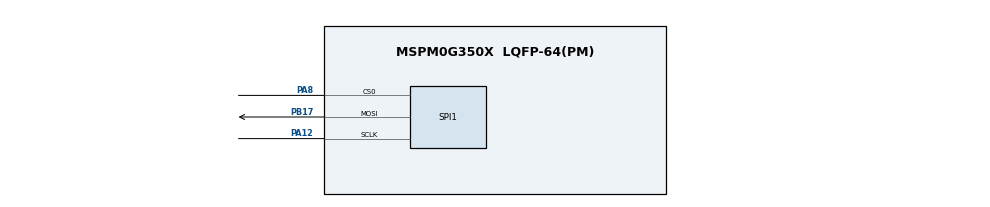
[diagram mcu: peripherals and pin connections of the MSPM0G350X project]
/**
 * @cliArgs --device "MSPM0G350X" --part "Default" --package "LQFP-64(PM)" --product "mspm0_sdk@2.05.01.01"
 * @versions {"tool":"1.24.0+4110"}
 */

/**
 * Import the modules used in this configuration.
 */
const SPI    = scripting.addModule("/ti/driverlib/SPI", {}, false);
const SPI1   = SPI.addInstance();
const SYSCTL = scripting.addModule("/ti/driverlib/SYSCTL");
const TIMER  = scripting.addModule("/ti/driverlib/TIMER", {}, false);
const TIMER1 = TIMER.addInstance();

/**
 * Write custom configuration values to the imported modules.
 */
const divider9       = system.clockTree["UDIV"];
divider9.divideValue = 2;

const multiplier2         = system.clockTree["PLL_QDIV"];
multiplier2.multiplyValue = 4;

const mux4       = system.clockTree["EXHFMUX"];
mux4.inputSelect = "EXHFMUX_XTAL";

const mux8       = system.clockTree["HSCLKMUX"];
mux8.inputSelect = "HSCLKMUX_SYSPLL0";

const mux12       = system.clockTree["SYSPLLMUX"];
mux12.inputSelect = "zSYSPLLMUX_HFCLK";

const pinFunction4       = system.clockTree["HFXT"];
pinFunction4.inputFreq   = 40;
pinFunction4.enable      = true;
pinFunction4.HFXTStartup = 16;

SPI1.$name                      = "SPI_0";
SPI1.polarity                   = "1";
SPI1.direction                  = "PICO";
SPI1.targetBitRate              = 20000000;
SPI1.sclkPinConfig.$name        = "ti_driverlib_gpio_GPIOPinGeneric0";
SPI1.mosiPinConfig.$name        = "ti_driverlib_gpio_GPIOPinGeneric1";
SPI1.cs0PinConfig.$name         = "ti_driverlib_gpio_GPIOPinGeneric3";
SPI1.peripheral.sclkPin.$assign = "PA12";
SPI1.peripheral.mosiPin.$assign = "PB17";
SPI1.peripheral.cs0Pin.$assign  = "PA8";

const Board = scripting.addModule("/ti/driverlib/Board", {}, false);

SYSCTL.forceDefaultClkConfig = true;
SYSCTL.clockTreeEn           = true;

TIMER1.$name              = "TIMER_0";
TIMER1.timerMode          = "PERIODIC";
TIMER1.interrupts         = ["ZERO"];
TIMER1.timerPeriod        = "10us";
TIMER1.peripheral.$assign = "TIMA0";

/**
 * Pinmux solution for unlocked pins/peripherals. This ensures that minor changes to the automatic solver in a future
 * version of the tool will not impact the pinmux you originally saw.  These lines can be completely deleted in order to
 * re-solve from scratch.
 */
pinFunction4.peripheral.$suggestSolution           = "SYSCTL";
pinFunction4.peripheral.hfxInPin.$suggestSolution  = "PA5";
pinFunction4.peripheral.hfxOutPin.$suggestSolution = "PA6";
SPI1.peripheral.$suggestSolution                   = "SPI0";
Board.peripheral.$suggestSolution                  = "DEBUGSS";
Board.peripheral.swclkPin.$suggestSolution         = "PA20";
Board.peripheral.swdioPin.$suggestSolution         = "PA19";
